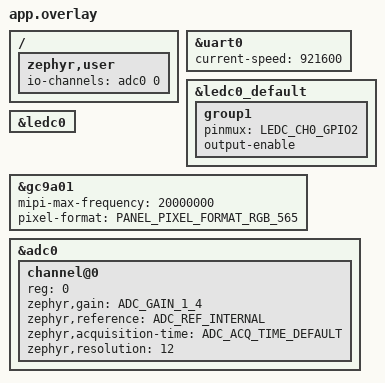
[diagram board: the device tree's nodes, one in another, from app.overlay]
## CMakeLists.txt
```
cmake_minimum_required(VERSION 3.20.0)
find_package(Zephyr REQUIRED HINTS $ENV{ZEPHYR_BASE})
project(esp32_face_os)

target_sources(app PRIVATE
    src/main.c
    src/ui_screens.c
    src/imu_qmi8658.c
    src/ble_scanner.c
    src/gpio_agent.c
    src/serial_proto.c
)
```

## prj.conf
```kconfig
CONFIG_MAIN_STACK_SIZE=8192
CONFIG_SYSTEM_WORKQUEUE_STACK_SIZE=4096
CONFIG_HEAP_MEM_POOL_SIZE=40960
CONFIG_SYS_HEAP_RUNTIME_STATS=y

# Display & Peripherals
CONFIG_DISPLAY=y
CONFIG_PWM=y
CONFIG_GPIO=y
CONFIG_I2C=y
CONFIG_ADC=y

# Touch Input
CONFIG_INPUT=y
CONFIG_INPUT_CST816S=y
CONFIG_INPUT_CST816S_INTERRUPT=y
CONFIG_LV_Z_POINTER_INPUT=y

# LVGL Configuration
CONFIG_LVGL=y
CONFIG_LV_MEM_CUSTOM=y
CONFIG_LV_Z_MEM_POOL_SIZE=49152
CONFIG_LV_COLOR_DEPTH_16=y
CONFIG_LV_USE_IMG=y
CONFIG_LV_USE_LABEL=y
CONFIG_LV_USE_BTN=y
CONFIG_LV_USE_ARC=y
CONFIG_LV_USE_BAR=y
CONFIG_LV_USE_SLIDER=y
CONFIG_LV_USE_SWITCH=y
CONFIG_LV_FONT_MONTSERRAT_12=y
CONFIG_LV_FONT_MONTSERRAT_14=y
CONFIG_LV_FONT_MONTSERRAT_18=y
CONFIG_LV_FONT_MONTSERRAT_24=y

# Bluetooth LE Observer (Passive Proximity Scanner)
CONFIG_BT=y
CONFIG_BT_OBSERVER=y
CONFIG_BT_DEVICE_NAME="CompanionFace"

# Serial / UART Protocol (921600 NDJSON, zero console/log interleaving on UART0)
CONFIG_SERIAL=y
CONFIG_UART_INTERRUPT_DRIVEN=y
CONFIG_PICOLIBC_IO_FLOAT=y
CONFIG_BOOT_BANNER=n
CONFIG_CONSOLE=n
CONFIG_UART_CONSOLE=n
CONFIG_LOG_BACKEND_UART=n
CONFIG_PRINTK=n
CONFIG_LOG=n
```

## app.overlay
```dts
#include <zephyr/dt-bindings/adc/adc.h>
#include <zephyr/dt-bindings/pinctrl/esp32s3-pinctrl.h>

/ {
	zephyr,user {
		io-channels = <&adc0 0>;
	};
};

&uart0 {
	current-speed = <921600>;
};

&ledc0_default {
	group1 {
		pinmux = <LEDC_CH0_GPIO2>;
		output-enable;
	};
};

&ledc0 {
	status = "okay";
};

&gc9a01 {
	mipi-max-frequency = <20000000>;
	pixel-format = <PANEL_PIXEL_FORMAT_RGB_565>;
};

&adc0 {
	status = "okay";
	#address-cells = <1>;
	#size-cells = <0>;

	channel@0 {
		reg = <0>;
		zephyr,gain = "ADC_GAIN_1_4";
		zephyr,reference = "ADC_REF_INTERNAL";
		zephyr,acquisition-time = <ADC_ACQ_TIME_DEFAULT>;
		zephyr,resolution = <12>;
	};
};
```

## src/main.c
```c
/*
 * Companion Face OS Front for Waveshare ESP32-S3-Touch-LCD-1.28-B
 * Built on Zephyr RTOS v3.7 + LVGL v8.4
 */

#include <stdio.h>
#include <zephyr/device.h>
#include <zephyr/devicetree.h>
#include <zephyr/drivers/display.h>
#include <zephyr/kernel.h>
#include <lvgl.h>

#include "ble_scanner.h"
#include "gpio_agent.h"
#include "imu_qmi8658.h"
#include "serial_proto.h"
#include "ui_screens.h"

static void on_face_tap_cb(bool currently_speaking)
{
    if (currently_speaking) {
        serial_send_json("{\"t\":\"evt\",\"src\":\"touch\",\"act\":\"stop_speech\"}");
        ui_set_emotion(FACE_IDLE);
    } else {
        serial_send_json("{\"t\":\"evt\",\"src\":\"touch\",\"act\":\"ptt_toggle\"}");
    }
}

static void on_cfg_change_cb(int bright, int vol, const char *mic_mode, int ble_en, int sleep_s)
{
    char buf[160];
    snprintf(buf, sizeof(buf),
             "{\"t\":\"evt\",\"src\":\"cfg\",\"bright\":%d,\"vol\":%d,\"mode\":\"%s\",\"ble_en\":%d,\"sleep_s\":%d}",
             bright, vol, mic_mode, ble_en, sleep_s);
    serial_send_json(buf);
}

static void on_dbg_test_call_cb(void)
{
    serial_send_json("{\"t\":\"evt\",\"src\":\"dbg\",\"act\":\"test_call\"}");
}

static void on_dbg_ble_refresh_cb(void)
{
    serial_send_ble_evt();
}

static void on_net_refresh_cb(void)
{
    serial_send_json("{\"t\":\"evt\",\"src\":\"net\",\"act\":\"refresh\"}");
}

int main(void)
{
    /* 1. Initialize Display & LVGL UI (PWM backlight GPIO 2 initialized in ui_screens_init) */
    const struct device *display_dev = DEVICE_DT_GET(DT_CHOSEN(zephyr_display));
    if (!device_is_ready(display_dev)) {
        return 0;
    }

    ui_callbacks_t ui_cbs = {
        .on_face_tap = on_face_tap_cb,
        .on_cfg_change = on_cfg_change_cb,
        .on_dbg_test_call = on_dbg_test_call_cb,
        .on_dbg_ble_refresh = on_dbg_ble_refresh_cb,
        .on_net_refresh = on_net_refresh_cb,
    };
    ui_screens_init(&ui_cbs);
    lv_task_handler();
    display_blanking_off(display_dev);

    /* 2. Initialize Subsystems (IMU launches dedicated 50Hz thread) */
    gpio_agent_init();
    imu_qmi8658_init();
    ble_scanner_init();
    serial_proto_init();

    serial_send_json("{\"t\":\"evt\",\"src\":\"sys\",\"act\":\"boot\",\"ver\":\"1.0\"}");

    uint32_t loop_tick = 0;

    while (1) {
        /* Drain UART NDJSON commands immediately */
        serial_proto_poll();

        /* Drain 50Hz IMU gesture events */
        imu_gesture_event_t imu_ev;
        while (imu_qmi8658_pop_gesture(&imu_ev)) {
            char ev[160];
            snprintf(ev, sizeof(ev),
                     "{\"t\":\"evt\",\"src\":\"imu\",\"gest\":\"%s\",\"ax\":%.2f,\"ay\":%.2f,\"az\":%.2f,\"temp\":%.1f}",
                     imu_gesture_to_str(imu_ev.gest),
                     (double)imu_ev.ax, (double)imu_ev.ay, (double)imu_ev.az,
                     (double)imu_ev.temp_c);
            serial_send_json(ev);
        }

        /* Animate procedural face at ~33 FPS (every 30ms) */
        if ((loop_tick % 3) == 0) {
            ui_screens_tick_anim();
        }

        /* Update Debug & Battery telemetry every 500ms */
        if ((loop_tick % 50) == 0) {
            ui_screens_update_telemetry();
        }

        /* Periodic 10-second heartbeat */
        if ((loop_tick % 1000) == 0 && loop_tick > 0) {
            char hb[96];
            snprintf(hb, sizeof(hb), "{\"t\":\"evt\",\"src\":\"sys\",\"act\":\"hb\",\"up\":%lld}",
                     k_uptime_get());
            serial_send_json(hb);
        }

        lv_task_handler();
        loop_tick++;
        k_sleep(K_MSEC(10));
    }

    return 0;
}
```

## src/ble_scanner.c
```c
#include "ble_scanner.h"

#include <stdio.h>
#include <string.h>
#include <zephyr/bluetooth/bluetooth.h>
#include <zephyr/bluetooth/hci.h>
#include <zephyr/kernel.h>
#include <zephyr/logging/log.h>

LOG_MODULE_REGISTER(ble_scanner, LOG_LEVEL_WRN);

#define BLE_STALE_MS 30000

static struct k_mutex ble_mutex;
static ble_device_entry_t dev_table[BLE_MAX_DEVICES];
static bool bt_initialized;
static bool scan_enabled;

static void sanitize_name(const uint8_t *src, size_t len, char *dst, size_t dst_size)
{
    size_t j = 0;
    for (size_t i = 0; i < len && j + 1 < dst_size; i++) {
        char c = (char)src[i];
        if (c >= 0x20 && c <= 0x7E && c != '"' && c != '\\') {
            dst[j++] = c;
        }
    }
    dst[j] = '\0';
}

static bool parse_ad_name_cb(struct bt_data *data, void *user_data)
{
    char *name_buf = (char *)user_data;
    if (data->type == BT_DATA_NAME_COMPLETE || data->type == BT_DATA_NAME_SHORTENED) {
        sanitize_name(data->data, data->data_len, name_buf, 32);
        return false; /* stop parsing */
    }
    return true;
}

static void prune_stale_locked(int64_t now)
{
    for (int i = 0; i < BLE_MAX_DEVICES; i++) {
        if (dev_table[i].active && (now - dev_table[i].last_seen_ms) > BLE_STALE_MS) {
            dev_table[i].active = false;
        }
    }
}

static void scan_cb(const bt_addr_le_t *addr, int8_t rssi, uint8_t type,
                    struct net_buf_simple *ad)
{
    ARG_UNUSED(type);

    char mac_str[18];
    snprintf(mac_str, sizeof(mac_str), "%02X:%02X:%02X:%02X:%02X:%02X",
             addr->a.val[5], addr->a.val[4], addr->a.val[3],
             addr->a.val[2], addr->a.val[1], addr->a.val[0]);

    char parsed_name[32] = {0};
    if (ad != NULL && ad->len > 0) {
        bt_data_parse(ad, parse_ad_name_cb, parsed_name);
    }

    int64_t now = k_uptime_get();

    k_mutex_lock(&ble_mutex, K_FOREVER);
    prune_stale_locked(now);

    int empty_idx = -1;
    int oldest_idx = 0;
    int64_t oldest_ts = INT64_MAX;
    int match_idx = -1;

    for (int i = 0; i < BLE_MAX_DEVICES; i++) {
        if (dev_table[i].active) {
            if (strcmp(dev_table[i].mac, mac_str) == 0 &&
                dev_table[i].addr_type == addr->type) {
                match_idx = i;
                break;
            }
            if (dev_table[i].last_seen_ms < oldest_ts) {
                oldest_ts = dev_table[i].last_seen_ms;
                oldest_idx = i;
            }
        } else if (empty_idx < 0) {
            empty_idx = i;
        }
    }

    int target = (match_idx >= 0) ? match_idx : ((empty_idx >= 0) ? empty_idx : oldest_idx);
    dev_table[target].active = true;
    dev_table[target].addr_type = addr->type;
    strncpy(dev_table[target].mac, mac_str, sizeof(dev_table[target].mac) - 1);
    dev_table[target].mac[sizeof(dev_table[target].mac) - 1] = '\0';
    dev_table[target].rssi = rssi;
    dev_table[target].last_seen_ms = now;

    if (parsed_name[0] != '\0') {
        strncpy(dev_table[target].name, parsed_name, sizeof(dev_table[target].name) - 1);
        dev_table[target].name[sizeof(dev_table[target].name) - 1] = '\0';
    } else if (match_idx < 0) {
        dev_table[target].name[0] = '\0';
    }

    k_mutex_unlock(&ble_mutex);
}

int ble_scanner_init(void)
{
    k_mutex_init(&ble_mutex);
    memset(dev_table, 0, sizeof(dev_table));

    int err = bt_enable(NULL);
    if (err) {
        LOG_ERR("bt_enable failed (%d)", err);
        return err;
    }
    bt_initialized = true;
    return ble_scanner_set_enabled(true);
}

int ble_scanner_set_enabled(bool enable)
{
    if (!bt_initialized) {
        return -ENODEV;
    }
    if (enable == scan_enabled) {
        return 0;
    }

    if (enable) {
        struct bt_le_scan_param scan_param = {
            .type = BT_LE_SCAN_TYPE_PASSIVE,
            .options = BT_LE_SCAN_OPT_NONE,
            .interval = BT_GAP_SCAN_FAST_INTERVAL,
            .window = BT_GAP_SCAN_FAST_WINDOW,
        };
        int err = bt_le_scan_start(&scan_param, scan_cb);
        if (err) {
            LOG_ERR("bt_le_scan_start failed (%d)", err);
            return err;
        }
        scan_enabled = true;
    } else {
        int err = bt_le_scan_stop();
        if (err) {
            LOG_ERR("bt_le_scan_stop failed (%d)", err);
            return err;
        }
        scan_enabled = false;
    }

    return 0;
}

bool ble_scanner_is_enabled(void)
{
    return scan_enabled;
}

int ble_scanner_get_count(void)
{
    int count = 0;
    int64_t now = k_uptime_get();

    k_mutex_lock(&ble_mutex, K_FOREVER);
    prune_stale_locked(now);
    for (int i = 0; i < BLE_MAX_DEVICES; i++) {
        if (dev_table[i].active) {
            count++;
        }
    }
    k_mutex_unlock(&ble_mutex);

    return count;
}

bool ble_scanner_get_strongest(char *mac_out, size_t mac_len,
                               char *name_out, size_t name_len,
                               int8_t *rssi_out)
{
    int64_t now = k_uptime_get();
    int best_idx = -1;
    int8_t best_rssi = INT8_MIN;

    k_mutex_lock(&ble_mutex, K_FOREVER);
    prune_stale_locked(now);
    for (int i = 0; i < BLE_MAX_DEVICES; i++) {
        if (dev_table[i].active && (best_idx < 0 || dev_table[i].rssi > best_rssi)) {
            best_rssi = dev_table[i].rssi;
            best_idx = i;
        }
    }

    if (best_idx >= 0) {
        if (mac_out && mac_len > 0) {
            strncpy(mac_out, dev_table[best_idx].mac, mac_len - 1);
            mac_out[mac_len - 1] = '\0';
        }
        if (name_out && name_len > 0) {
            strncpy(name_out, dev_table[best_idx].name, name_len - 1);
            name_out[name_len - 1] = '\0';
        }
        if (rssi_out) {
            *rssi_out = best_rssi;
        }
    }
    k_mutex_unlock(&ble_mutex);

    return best_idx >= 0;
}

int ble_scanner_format_json_ex(char *buf, size_t len, int *cnt_out)
{
    if (!buf || len < 3) {
        return -EINVAL;
    }

    int64_t now = k_uptime_get();
    size_t pos = 0;
    buf[pos++] = '[';
    bool first = true;
    int count = 0;

    k_mutex_lock(&ble_mutex, K_FOREVER);
    prune_stale_locked(now);

    for (int i = 0; i < BLE_MAX_DEVICES; i++) {
        if (!dev_table[i].active) {
            continue;
        }
        char entry[128];
        int n = snprintf(entry, sizeof(entry),
                         "%s{\"mac\":\"%s\",\"type\":%u,\"name\":\"%s\",\"rssi\":%d}",
                         first ? "" : ",",
                         dev_table[i].mac,
                         (unsigned int)dev_table[i].addr_type,
                         dev_table[i].name[0] ? dev_table[i].name : "?",
                         (int)dev_table[i].rssi);
        if (n < 0 || (size_t)n >= sizeof(entry) || pos + (size_t)n + 2 > len) {
            break;
        }
        memcpy(buf + pos, entry, (size_t)n);
        pos += (size_t)n;
        first = false;
        count++;
    }
    k_mutex_unlock(&ble_mutex);

    if (cnt_out) {
        *cnt_out = count;
    }
    buf[pos++] = ']';
    buf[pos] = '\0';
    return (int)pos;
}

int ble_scanner_format_json(char *buf, size_t len)
{
    return ble_scanner_format_json_ex(buf, len, NULL);
}
```

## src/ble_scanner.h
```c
#ifndef BLE_SCANNER_H
#define BLE_SCANNER_H

#include <stdbool.h>
#include <stddef.h>
#include <stdint.h>

#define BLE_MAX_DEVICES 32

typedef struct {
    bool active;
    uint8_t addr_type;
    char mac[18];
    char name[32];
    int8_t rssi;
    int64_t last_seen_ms;
} ble_device_entry_t;

/**
 * @brief Initialize Zephyr BLE stack and start passive observer scanning.
 * @return 0 on success, negative errno on failure.
 */
int ble_scanner_init(void);

/**
 * @brief Enable or pause background BLE passive scanning.
 */
int ble_scanner_set_enabled(bool enable);

/**
 * @brief Check whether BLE scanning is currently active.
 */
bool ble_scanner_is_enabled(void);

/**
 * @brief Return count of active devices seen within the last 30 seconds.
 */
int ble_scanner_get_count(void);

/**
 * @brief Retrieve strongest currently visible device (if any).
 * @return true if at least one active device exists.
 */
bool ble_scanner_get_strongest(char *mac_out, size_t mac_len,
                               char *name_out, size_t name_len,
                               int8_t *rssi_out);

/**
 * @brief Format active BLE devices as a JSON array into buf: [{"mac":"...","type":0,"name":"...","rssi":-50},...]
 */
int ble_scanner_format_json(char *buf, size_t len);

/**
 * @brief Format active BLE devices as a JSON array and output exact serialized count under one lock.
 */
int ble_scanner_format_json_ex(char *buf, size_t len, int *cnt_out);

#endif /* BLE_SCANNER_H */
```

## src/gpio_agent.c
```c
#include "gpio_agent.h"

#include <errno.h>
#include <stdio.h>
#include <string.h>
#include <zephyr/device.h>
#include <zephyr/devicetree.h>
#include <zephyr/drivers/adc.h>
#include <zephyr/drivers/gpio.h>
#include <zephyr/kernel.h>
#include <zephyr/logging/log.h>

LOG_MODULE_REGISTER(gpio_agent, LOG_LEVEL_WRN);

static const int allowed_pins[] = { 15, 16, 17, 18, 21, 33, 34, 35, 36, 37 };
#define NUM_ALLOWED_PINS (sizeof(allowed_pins) / sizeof(allowed_pins[0]))

static const struct device *gpio0_dev;
static const struct device *gpio1_dev;
static bool pin_configured_out[NUM_ALLOWED_PINS];
static bool pin_configured_in[NUM_ALLOWED_PINS];
static char last_gpio_status[40] = "GPIO: idle";
static struct k_mutex gpio_mutex;

#if DT_NODE_EXISTS(DT_PATH(zephyr_user)) && DT_NODE_HAS_PROP(DT_PATH(zephyr_user), io_channels)
static const struct adc_dt_spec vbat_adc = ADC_DT_SPEC_GET_BY_IDX(DT_PATH(zephyr_user), 0);
static bool adc_ready;
#else
static bool adc_ready;
#endif

static int resolve_pin(int pin, const struct device **port_out, gpio_pin_t *pin_out, int *slot_out)
{
    for (int i = 0; i < (int)NUM_ALLOWED_PINS; i++) {
        if (allowed_pins[i] == pin) {
            if (pin < 32) {
                if (!gpio0_dev || !device_is_ready(gpio0_dev)) {
                    return -ENODEV;
                }
                *port_out = gpio0_dev;
                *pin_out = (gpio_pin_t)pin;
            } else {
                if (!gpio1_dev || !device_is_ready(gpio1_dev)) {
                    return -ENODEV;
                }
                *port_out = gpio1_dev;
                *pin_out = (gpio_pin_t)(pin - 32);
            }
            if (slot_out) {
                *slot_out = i;
            }
            return 0;
        }
    }
    return -EACCES;
}

int gpio_agent_init(void)
{
    k_mutex_init(&gpio_mutex);
    memset(pin_configured_out, 0, sizeof(pin_configured_out));
    memset(pin_configured_in, 0, sizeof(pin_configured_in));

    gpio0_dev = DEVICE_DT_GET(DT_NODELABEL(gpio0));
    gpio1_dev = DEVICE_DT_GET(DT_NODELABEL(gpio1));

#if DT_NODE_EXISTS(DT_PATH(zephyr_user)) && DT_NODE_HAS_PROP(DT_PATH(zephyr_user), io_channels)
    if (adc_is_ready_dt(&vbat_adc)) {
        int err = adc_channel_setup_dt(&vbat_adc);
        if (err == 0) {
            adc_ready = true;
        } else {
            LOG_WRN("adc_channel_setup_dt failed: %d", err);
        }
    }
#endif

    return 0;
}

static int configure_pin_locked(int pin, const struct device *port, gpio_pin_t hw_pin,
                                int slot, const char *dir, const char *pull, int initial_val)
{
    gpio_flags_t flags = 0;
    bool is_out = (dir != NULL && strcmp(dir, "out") == 0);

    if (is_out) {
        flags = GPIO_INPUT | (initial_val ? GPIO_OUTPUT_HIGH : GPIO_OUTPUT_LOW);
    } else {
        flags = GPIO_INPUT;
        if (pull != NULL) {
            if (strcmp(pull, "up") == 0) {
                flags |= GPIO_PULL_UP;
            } else if (strcmp(pull, "down") == 0) {
                flags |= GPIO_PULL_DOWN;
            }
        }
    }

    int err = gpio_pin_configure(port, hw_pin, flags);
    if (err == 0) {
        pin_configured_out[slot] = is_out;
        pin_configured_in[slot] = !is_out;
        snprintf(last_gpio_status, sizeof(last_gpio_status), "P%d %s=%d",
                 pin, is_out ? "OUT" : "IN", is_out ? (initial_val ? 1 : 0) : 0);
    } else {
        snprintf(last_gpio_status, sizeof(last_gpio_status), "P%d ERR %d", pin, err);
    }
    return err;
}

static bool is_valid_dir(const char *dir)
{
    return dir != NULL && (strcmp(dir, "in") == 0 || strcmp(dir, "out") == 0);
}

static bool is_valid_pull(const char *pull)
{
    return pull == NULL || strcmp(pull, "none") == 0 ||
           strcmp(pull, "up") == 0 || strcmp(pull, "down") == 0;
}

int gpio_agent_configure(int pin, const char *dir, const char *pull, int initial_val)
{
    if (!is_valid_dir(dir) || !is_valid_pull(pull)) {
        return -EINVAL;
    }

    const struct device *port = NULL;
    gpio_pin_t hw_pin = 0;
    int slot = -1;

    int err = resolve_pin(pin, &port, &hw_pin, &slot);
    if (err != 0) {
        k_mutex_lock(&gpio_mutex, K_FOREVER);
        snprintf(last_gpio_status, sizeof(last_gpio_status), "GPIO %d: DENIED", pin);
        k_mutex_unlock(&gpio_mutex);
        return err;
    }

    k_mutex_lock(&gpio_mutex, K_FOREVER);
    err = configure_pin_locked(pin, port, hw_pin, slot, dir, pull, initial_val);
    k_mutex_unlock(&gpio_mutex);

    return err;
}

int gpio_agent_set(int pin, int val)
{
    const struct device *port = NULL;
    gpio_pin_t hw_pin = 0;
    int slot = -1;

    int err = resolve_pin(pin, &port, &hw_pin, &slot);
    if (err != 0) {
        return err;
    }

    k_mutex_lock(&gpio_mutex, K_FOREVER);
    if (!pin_configured_out[slot]) {
        err = configure_pin_locked(pin, port, hw_pin, slot, "out", "none", val ? 1 : 0);
        k_mutex_unlock(&gpio_mutex);
        return err;
    }

    err = gpio_pin_set(port, hw_pin, val ? 1 : 0);
    if (err == 0) {
        snprintf(last_gpio_status, sizeof(last_gpio_status), "P%d OUT=%d", pin, val ? 1 : 0);
    }
    k_mutex_unlock(&gpio_mutex);

    return err;
}

int gpio_agent_get(int pin, int *val_out)
{
    const struct device *port = NULL;
    gpio_pin_t hw_pin = 0;
    int slot = -1;

    int err = resolve_pin(pin, &port, &hw_pin, &slot);
    if (err != 0) {
        return err;
    }

    k_mutex_lock(&gpio_mutex, K_FOREVER);
    if (!pin_configured_out[slot] && !pin_configured_in[slot]) {
        err = configure_pin_locked(pin, port, hw_pin, slot, "in", "none", 0);
        if (err != 0) {
            k_mutex_unlock(&gpio_mutex);
            return err;
        }
    }

    int val = gpio_pin_get(port, hw_pin);
    if (val < 0) {
        k_mutex_unlock(&gpio_mutex);
        return val;
    }

    if (val_out) {
        *val_out = val;
    }

    snprintf(last_gpio_status, sizeof(last_gpio_status), "P%d READ=%d", pin, val);
    k_mutex_unlock(&gpio_mutex);

    return 0;
}

int gpio_agent_read_vbat_mv(void)
{
#if DT_NODE_EXISTS(DT_PATH(zephyr_user)) && DT_NODE_HAS_PROP(DT_PATH(zephyr_user), io_channels)
    k_mutex_lock(&gpio_mutex, K_FOREVER);
    if (!adc_ready) {
        k_mutex_unlock(&gpio_mutex);
        return 0;
    }

    int16_t buf = 0;
    struct adc_sequence seq = {
        .buffer = &buf,
        .buffer_size = sizeof(buf),
    };

    if (adc_sequence_init_dt(&vbat_adc, &seq) < 0) {
        k_mutex_unlock(&gpio_mutex);
        return 0;
    }
    if (adc_read_dt(&vbat_adc, &seq) < 0) {
        k_mutex_unlock(&gpio_mutex);
        return 0;
    }
    k_mutex_unlock(&gpio_mutex);

    int32_t mv = buf;
    if (adc_raw_to_millivolts_dt(&vbat_adc, &mv) < 0) {
        /* Fallback for 12-bit ADC with ~3.1V full scale at 11dB/1_4 gain */
        mv = ((int32_t)buf * 3100) / 4095;
    }

    /* Waveshare 200k + 100k resistor divider scales Vbat by 1/3 */
    return (int)(mv * 3);
#else
    return 0;
#endif
}

void gpio_agent_get_status_str(char *buf, size_t len)
{
    if (!buf || len == 0) return;
    k_mutex_lock(&gpio_mutex, K_FOREVER);
    strncpy(buf, last_gpio_status, len - 1);
    buf[len - 1] = '\0';
    k_mutex_unlock(&gpio_mutex);
}
```

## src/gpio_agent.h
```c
#ifndef GPIO_AGENT_H
#define GPIO_AGENT_H

#include <stdbool.h>
#include <stddef.h>

/**
 * @brief Initialize GPIO agent and battery ADC channel.
 */
int gpio_agent_init(void);

/**
 * @brief Configure an allowlisted header GPIO pin dynamically.
 * @param pin GPIO number (allowlist: 15,16,17,18,21,33,34,35,36,37)
 * @param dir "in" or "out"
 * @param pull "none", "up", or "down"
 * @param initial_val 0 or 1 (for output)
 * @return 0 on success, -EACCES if reserved, negative errno otherwise.
 */
int gpio_agent_configure(int pin, const char *dir, const char *pull, int initial_val);

/**
 * @brief Set an allowlisted GPIO output level (auto-configures as output if needed).
 */
int gpio_agent_set(int pin, int val);

/**
 * @brief Read an allowlisted GPIO pin state (returns 0 or 1 in val_out).
 */
int gpio_agent_get(int pin, int *val_out);

/**
 * @brief Read battery voltage in millivolts (scaled for 1/3 voltage divider on GPIO 1).
 */
int gpio_agent_read_vbat_mv(void);

/**
 * @brief Get human-readable summary of last agent GPIO operation for the debug screen.
 */
void gpio_agent_get_status_str(char *buf, size_t len);

#endif /* GPIO_AGENT_H */
```

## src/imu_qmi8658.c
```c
#include "imu_qmi8658.h"

#include <math.h>
#include <string.h>
#include <zephyr/device.h>
#include <zephyr/drivers/i2c.h>
#include <zephyr/kernel.h>
#include <zephyr/logging/log.h>
#include <zephyr/sys/byteorder.h>

LOG_MODULE_REGISTER(imu_qmi8658, LOG_LEVEL_WRN);

#define QMI8658_ADDR_PRIMARY   0x6B
#define QMI8658_ADDR_ALT       0x6A

#define QMI8658_REG_WHO_AM_I   0x00
#define QMI8658_REG_CTRL1      0x02
#define QMI8658_REG_CTRL2      0x03
#define QMI8658_REG_CTRL3      0x04
#define QMI8658_REG_CTRL7      0x08
#define QMI8658_REG_TEMP_L     0x33

#define QMI8658_WHO_AM_I_VAL   0x05

#define GESTURE_COOLDOWN_MS    800
#define IMU_THREAD_STACK_SIZE  2048
#define IMU_THREAD_PRIO        K_PRIO_PREEMPT(2)

typedef enum {
    TAP_IDLE = 0,
    TAP_FIRST_ACTIVE,
    TAP_WAIT_SECOND,
    TAP_SECOND_ACTIVE,
} tap_state_t;

static const struct device *i2c_dev;
static struct k_mutex imu_mutex;
static imu_data_t g_imu;
static int shake_score;
static bool was_tilted;
static bool lp_init;
static float lp_ax, lp_ay, lp_az;
static int lp_freeze_ticks;
static bool prev_init;
static float prev_ax, prev_ay, prev_az;
static int rest_flat_ticks;
static bool was_resting_flat;
static int pickup_ticks;
static int pickup_drop_ticks;
static bool pickup_ref_set;
static bool pickup_active;
static bool pickup_dipped;
static float pickup_ref_ax, pickup_ref_ay;
static float pickup_dir_ax, pickup_dir_ay;
static tap_state_t tap_state;
static int64_t tap1_ms;
static int64_t tap2_ms;
static int tap_quiet_ticks;
static int tap2_steady_ticks;
static float tap1_base_ax, tap1_base_ay, tap1_base_az;
static float tap2_base_ax, tap2_base_ay, tap2_base_az;
static int64_t last_shake_ms;

K_MSGQ_DEFINE(imu_evt_msgq, sizeof(imu_gesture_event_t), 8, 4);
K_THREAD_STACK_DEFINE(imu_thread_stack, IMU_THREAD_STACK_SIZE);
static struct k_thread imu_thread_data;
static void imu_thread_fn(void *p1, void *p2, void *p3);

static int qmi_write_reg(uint8_t addr, uint8_t reg, uint8_t val)
{
    uint8_t buf[2] = { reg, val };
    return i2c_write(i2c_dev, buf, sizeof(buf), addr);
}

static int qmi_read_regs(uint8_t addr, uint8_t reg, uint8_t *dst, size_t len)
{
    return i2c_write_read(i2c_dev, addr, &reg, 1, dst, len);
}

static int try_probe_addr(uint8_t addr)
{
    uint8_t who = 0;
    int ret = qmi_read_regs(addr, QMI8658_REG_WHO_AM_I, &who, 1);
    if (ret < 0) {
        return ret;
    }
    if (who != QMI8658_WHO_AM_I_VAL) {
        return -ENODEV;
    }
    return 0;
}

int imu_qmi8658_init(void)
{
    k_mutex_init(&imu_mutex);
    memset(&g_imu, 0, sizeof(g_imu));
    shake_score = 0;
    was_tilted = false;
    lp_init = false;
    lp_ax = lp_ay = lp_az = 0.0f;
    lp_freeze_ticks = 0;
    prev_init = false;
    prev_ax = prev_ay = prev_az = 0.0f;
    rest_flat_ticks = 0;
    was_resting_flat = false;
    pickup_ticks = 0;
    pickup_drop_ticks = 0;
    pickup_ref_set = false;
    pickup_active = false;
    pickup_dipped = false;
    pickup_ref_ax = pickup_ref_ay = 0.0f;
    pickup_dir_ax = pickup_dir_ay = 0.0f;
    tap_state = TAP_IDLE;
    tap1_ms = 0;
    tap2_ms = 0;
    tap_quiet_ticks = 0;
    tap2_steady_ticks = 0;
    tap1_base_ax = tap1_base_ay = tap1_base_az = 0.0f;
    tap2_base_ax = tap2_base_ay = tap2_base_az = 0.0f;
    last_shake_ms = -1000;

    i2c_dev = DEVICE_DT_GET(DT_NODELABEL(i2c1));
    if (!device_is_ready(i2c_dev)) {
        LOG_ERR("i2c1 not ready");
        return -ENODEV;
    }

    uint8_t addr = QMI8658_ADDR_PRIMARY;
    if (try_probe_addr(addr) != 0) {
        addr = QMI8658_ADDR_ALT;
        if (try_probe_addr(addr) != 0) {
            LOG_ERR("QMI8658 not found at 0x6B or 0x6A");
            return -ENODEV;
        }
    }

    /* CTRL1: auto-increment address, little endian */
    if (qmi_write_reg(addr, QMI8658_REG_CTRL1, 0x40) < 0) return -EIO;
    /* CTRL2: Accel +/-8g (0x2_), 250Hz (0x_5) */
    if (qmi_write_reg(addr, QMI8658_REG_CTRL2, 0x25) < 0) return -EIO;
    /* CTRL3: Gyro +/-512dps (0x5_), 250Hz (0x_5) */
    if (qmi_write_reg(addr, QMI8658_REG_CTRL3, 0x55) < 0) return -EIO;
    /* CTRL7: Enable Accel + Gyro */
    if (qmi_write_reg(addr, QMI8658_REG_CTRL7, 0x03) < 0) return -EIO;

    k_mutex_lock(&imu_mutex, K_FOREVER);
    g_imu.ready = true;
    g_imu.addr = addr;
    g_imu.last_gesture = IMU_GESTURE_NONE;
    k_mutex_unlock(&imu_mutex);

    k_thread_create(&imu_thread_data, imu_thread_stack,
                    K_THREAD_STACK_SIZEOF(imu_thread_stack),
                    imu_thread_fn, NULL, NULL, NULL,
                    IMU_THREAD_PRIO, 0, K_NO_WAIT);
    k_thread_name_set(&imu_thread_data, "imu_50hz");

    return 0;
}

static imu_gesture_t imu_qmi8658_poll(imu_data_t *out)
{
    imu_gesture_t triggered = IMU_GESTURE_NONE;
    bool ready = false;
    uint8_t addr = 0;

    k_mutex_lock(&imu_mutex, K_FOREVER);
    ready = g_imu.ready;
    addr = g_imu.addr;
    k_mutex_unlock(&imu_mutex);

    if (!ready || i2c_dev == NULL) {
        if (out) {
            imu_qmi8658_get_latest(out);
        }
        return IMU_GESTURE_NONE;
    }

    uint8_t raw[14];
    if (qmi_read_regs(addr, QMI8658_REG_TEMP_L, raw, sizeof(raw)) < 0) {
        if (out) {
            imu_qmi8658_get_latest(out);
        }
        return IMU_GESTURE_NONE;
    }

    int16_t raw_temp = (int16_t)sys_get_le16(&raw[0]);
    int16_t raw_ax   = (int16_t)sys_get_le16(&raw[2]);
    int16_t raw_ay   = (int16_t)sys_get_le16(&raw[4]);
    int16_t raw_az   = (int16_t)sys_get_le16(&raw[6]);
    int16_t raw_gx   = (int16_t)sys_get_le16(&raw[8]);
    int16_t raw_gy   = (int16_t)sys_get_le16(&raw[10]);
    int16_t raw_gz   = (int16_t)sys_get_le16(&raw[12]);

    float ax = ((float)raw_ax) * (9.80665f / 4096.0f);
    float ay = ((float)raw_ay) * (9.80665f / 4096.0f);
    float az = ((float)raw_az) * (9.80665f / 4096.0f);
    float gx = ((float)raw_gx) / 64.0f;
    float gy = ((float)raw_gy) / 64.0f;
    float gz = ((float)raw_gz) / 64.0f;
    float temp_c = ((float)raw_temp) / 256.0f;

    int64_t now = k_uptime_get();

    if (!prev_init) {
        prev_ax = ax;
        prev_ay = ay;
        prev_az = az;
        prev_init = true;
    }
    float jx = ax - prev_ax;
    float jy = ay - prev_ay;
    float jz = az - prev_az;
    float jerk = sqrtf(jx * jx + jy * jy + jz * jz);
    prev_ax = ax;
    prev_ay = ay;
    prev_az = az;

    float a_mag = sqrtf(ax * ax + ay * ay + az * az);

    if (!lp_init) {
        lp_ax = ax;
        lp_ay = ay;
        lp_az = az;
        lp_init = true;
        lp_freeze_ticks = 0;
    }

    float dx = ax - lp_ax;
    float dy = ay - lp_ay;
    float dz = az - lp_az;
    float dyn_mag = sqrtf(dx * dx + dy * dy + dz * dz);

    /* Freeze low-pass gravity adaptation on sharp tap impulses (up to 15 ticks = 300ms),
     * while allowing steady 1g orientation changes to track gravity smoothly. */
    bool steady_1g = (jerk < 3.0f) && (fabsf(a_mag - 9.80665f) < 1.5f);
    if (dyn_mag <= 2.2f || steady_1g || lp_freeze_ticks >= 15) {
        lp_ax += 0.15f * (ax - lp_ax);
        lp_ay += 0.15f * (ay - lp_ay);
        lp_az += 0.15f * (az - lp_az);
        dx = ax - lp_ax;
        dy = ay - lp_ay;
        dz = az - lp_az;
        dyn_mag = sqrtf(dx * dx + dy * dy + dz * dz);
        lp_freeze_ticks = 0;
    } else {
        lp_freeze_ticks++;
    }

    float in_plane = sqrtf(ax * ax + ay * ay);
    float gyro_mag = fabsf(gx) + fabsf(gy) + fabsf(gz);
    bool is_tilted = (fabsf(ax) > 6.5f) || (fabsf(ay) > 6.5f);

    if (dyn_mag > 7.0f && !steady_1g) {
        shake_score += 2;
        if (shake_score > 16) {
            shake_score = 16;
        }
    } else if (shake_score > 0) {
        shake_score--;
    }

    if (was_resting_flat) {
        if (in_plane > 5.5f) {
            pickup_active = true;
            pickup_drop_ticks = 0;
            if (!pickup_ref_set || pickup_dipped) {
                pickup_ref_ax = ax;
                pickup_ref_ay = ay;
                pickup_ref_set = true;
                pickup_dipped = false;
            } else if ((shake_score >= 10) ||
                       (shake_score >= 4 && dyn_mag > 7.0f && a_mag > 12.0f &&
                        (ax * pickup_ref_ax + ay * pickup_ref_ay) < -15.0f)) {
                /* High-energy shake or lateral reversal: not a pickup/twist */
                was_resting_flat = false;
                rest_flat_ticks = 0;
                pickup_ticks = 0;
                pickup_drop_ticks = 0;
                pickup_ref_set = false;
                pickup_active = false;
                pickup_dipped = false;
            }
        } else {
            bool clear_flat = false;
            if (shake_score >= 4) {
                clear_flat = true;
            } else if (pickup_active) {
                if (in_plane < 3.5f) {
                    clear_flat = true;
                } else if (in_plane <= 4.5f) {
                    pickup_drop_ticks++;
                    pickup_dipped = true;
                    if (pickup_drop_ticks >= 2) {
                        clear_flat = true;
                    }
                } else {
                    pickup_drop_ticks = 0;
                }
            }
            if (clear_flat) {
                was_resting_flat = false;
                rest_flat_ticks = 0;
                pickup_ticks = 0;
                pickup_drop_ticks = 0;
                pickup_ref_set = false;
                pickup_active = false;
                pickup_dipped = false;
            }
        }
    }

    if (shake_score >= 10 || (now - last_shake_ms) <= 500) {
        tap_state = TAP_IDLE;
    }

    if (in_plane < 3.0f && dyn_mag < 1.5f && gyro_mag < 30.0f) {
        if (rest_flat_ticks < 25) {
            rest_flat_ticks++;
        }
        if (rest_flat_ticks >= 15) {
            was_resting_flat = true;
            pickup_ref_set = false;
            pickup_drop_ticks = 0;
            pickup_active = false;
            pickup_dipped = false;
        }
    } else {
        rest_flat_ticks = 0;
    }

    bool dbl_tap_fired = false;
    switch (tap_state) {
    case TAP_IDLE:
        if (dyn_mag > 4.0f && gyro_mag < 220.0f &&
            (now - last_shake_ms) > 500 && shake_score < 8) {
            tap1_ms = now;
            tap1_base_ax = lp_ax;
            tap1_base_ay = lp_ay;
            tap1_base_az = lp_az;
            tap_quiet_ticks = 0;
            tap_state = TAP_FIRST_ACTIVE;
        }
        break;
    case TAP_FIRST_ACTIVE:
        if ((now - tap1_ms) > 140) {
            tap_state = TAP_IDLE;
        } else if (dyn_mag < 2.2f) {
            float bx = ax - tap1_base_ax;
            float by = ay - tap1_base_ay;
            float bz = az - tap1_base_az;
            float bdiff = sqrtf(bx * bx + by * by + bz * bz);
            if (bdiff > 3.5f) {
                tap_state = TAP_IDLE;
            } else {
                tap_quiet_ticks = 1;
                tap2_base_ax = lp_ax;
                tap2_base_ay = lp_ay;
                tap2_base_az = lp_az;
                tap_state = TAP_WAIT_SECOND;
            }
        }
        break;
    case TAP_WAIT_SECOND: {
        int64_t dt = now - tap1_ms;
        if (dt > 450) {
            tap_state = TAP_IDLE;
        } else if (dyn_mag < 2.2f) {
            tap_quiet_ticks++;
            tap2_base_ax = lp_ax;
            tap2_base_ay = lp_ay;
            tap2_base_az = lp_az;
        } else if (dt < 120) {
            if (dyn_mag > 4.0f) {
                tap_state = TAP_IDLE;
            } else {
                tap_quiet_ticks = 0;
            }
        } else if (dyn_mag > 4.0f && gyro_mag < 220.0f) {
            if (tap_quiet_ticks >= 2) {
                tap2_ms = now;
                tap2_steady_ticks = 0;
                tap_quiet_ticks = 0;
                tap_state = TAP_SECOND_ACTIVE;
            } else {
                tap_state = TAP_IDLE;
            }
        }
        break;
    }
    case TAP_SECOND_ACTIVE: {
        int64_t dt2 = now - tap2_ms;
        float bx = ax - tap2_base_ax;
        float by = ay - tap2_base_ay;
        float bz = az - tap2_base_az;
        float bdiff = sqrtf(bx * bx + by * by + bz * bz);
        if (dt2 > 120) {
            tap_state = TAP_IDLE;
        } else if (steady_1g && bdiff > 3.5f) {
            tap2_steady_ticks++;
            if (tap2_steady_ticks >= 4) {
                tap_state = TAP_IDLE;
            }
        } else if (dyn_mag < 2.2f) {
            if (bdiff > 3.5f) {
                tap_state = TAP_IDLE;
            } else {
                tap_quiet_ticks++;
                if (tap_quiet_ticks >= 3 && shake_score < 10) {
                    dbl_tap_fired = true;
                    tap_state = TAP_IDLE;
                }
            }
        } else {
            if (tap_quiet_ticks > 0 && dyn_mag > 3.5f) {
                tap_state = TAP_IDLE;
            } else {
                tap_quiet_ticks = 0;
            }
        }
        break;
    }
    }

    bool settled = steady_1g || (dyn_mag <= 7.0f);
    bool flat_lateral = (fabsf(az) > 8.5f);
    if (was_resting_flat && in_plane > 5.5f && settled && shake_score < 4 && !flat_lateral) {
        if (pickup_ticks == 0) {
            pickup_dir_ax = ax;
            pickup_dir_ay = ay;
            pickup_ticks = 1;
        } else {
            float dot = ax * pickup_dir_ax + ay * pickup_dir_ay;
            float dir_m2 = pickup_dir_ax * pickup_dir_ax + pickup_dir_ay * pickup_dir_ay;
            float cur_m2 = ax * ax + ay * ay;
            if (dot <= 0.0f || (dot * dot) < 0.88f * dir_m2 * cur_m2) {
                pickup_dir_ax = ax;
                pickup_dir_ay = ay;
                pickup_ticks = 1;
            } else {
                pickup_ticks++;
            }
        }
    } else {
        pickup_ticks = 0;
    }

    k_mutex_lock(&imu_mutex, K_FOREVER);
    g_imu.ax = ax;
    g_imu.ay = ay;
    g_imu.az = az;
    g_imu.gx = gx;
    g_imu.gy = gy;
    g_imu.gz = gz;
    g_imu.temp_c = temp_c;

    if ((now - g_imu.last_gesture_ms) >= GESTURE_COOLDOWN_MS) {
        if (shake_score >= 10 && (!was_resting_flat || in_plane <= 5.5f)) {
            triggered = IMU_GESTURE_SHAKE;
            g_imu.last_gesture = IMU_GESTURE_SHAKE;
            g_imu.last_gesture_ms = now;
            shake_score = 0;
            last_shake_ms = now;
            tap_state = TAP_IDLE;
            was_resting_flat = false;
            rest_flat_ticks = 0;
            pickup_ticks = 0;
            pickup_drop_ticks = 0;
            pickup_ref_set = false;
            pickup_active = false;
            pickup_dipped = false;
        } else if (shake_score < 4 && was_resting_flat && pickup_ticks >= 3) {
            triggered = IMU_GESTURE_PICKUP;
            g_imu.last_gesture = IMU_GESTURE_PICKUP;
            g_imu.last_gesture_ms = now;
            was_resting_flat = false;
            rest_flat_ticks = 0;
            pickup_ticks = 0;
            pickup_drop_ticks = 0;
            pickup_ref_set = false;
            pickup_active = false;
            pickup_dipped = false;
        } else if (dbl_tap_fired) {
            triggered = IMU_GESTURE_DOUBLE_TAP;
            g_imu.last_gesture = IMU_GESTURE_DOUBLE_TAP;
            g_imu.last_gesture_ms = now;
        } else if (shake_score < 4 && is_tilted && !was_tilted &&
                   settled && !was_resting_flat && !flat_lateral) {
            triggered = IMU_GESTURE_TILT;
            g_imu.last_gesture = IMU_GESTURE_TILT;
            g_imu.last_gesture_ms = now;
        }
    }

    if (pickup_ticks >= 3) {
        was_resting_flat = false;
        rest_flat_ticks = 0;
        pickup_ticks = 0;
        pickup_drop_ticks = 0;
        pickup_ref_set = false;
        pickup_active = false;
        pickup_dipped = false;
    }
    was_tilted = is_tilted;

    if (out) {
        *out = g_imu;
    }
    k_mutex_unlock(&imu_mutex);

    return triggered;
}

static void imu_thread_fn(void *p1, void *p2, void *p3)
{
    ARG_UNUSED(p1);
    ARG_UNUSED(p2);
    ARG_UNUSED(p3);

    int64_t next_ms = k_uptime_get();
    while (1) {
        imu_data_t snap;
        imu_gesture_t gest = imu_qmi8658_poll(&snap);
        if (gest != IMU_GESTURE_NONE) {
            imu_gesture_event_t ev = {
                .gest = gest,
                .ax = snap.ax,
                .ay = snap.ay,
                .az = snap.az,
                .temp_c = snap.temp_c,
            };
            k_msgq_put(&imu_evt_msgq, &ev, K_NO_WAIT);
        }

        next_ms += 20;
        int64_t rem = next_ms - k_uptime_get();
        if (rem > 0) {
            k_msleep((int32_t)rem);
        } else if (rem < -100) {
            next_ms = k_uptime_get();
        }
    }
}

bool imu_qmi8658_pop_gesture(imu_gesture_event_t *out)
{
    if (!out) return false;
    return k_msgq_get(&imu_evt_msgq, out, K_NO_WAIT) == 0;
}

void imu_qmi8658_get_latest(imu_data_t *out)
{
    if (!out) return;
    k_mutex_lock(&imu_mutex, K_FOREVER);
    *out = g_imu;
    k_mutex_unlock(&imu_mutex);
}

const char *imu_gesture_to_str(imu_gesture_t g)
{
    switch (g) {
    case IMU_GESTURE_SHAKE:
        return "shake";
    case IMU_GESTURE_TILT:
        return "tilt";
    case IMU_GESTURE_PICKUP:
        return "pickup";
    case IMU_GESTURE_DOUBLE_TAP:
        return "double_tap";
    default:
        return "none";
    }
}
```

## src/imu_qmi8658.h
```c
#ifndef IMU_QMI8658_H
#define IMU_QMI8658_H

#include <stdbool.h>
#include <stdint.h>

typedef enum {
    IMU_GESTURE_NONE = 0,
    IMU_GESTURE_SHAKE,
    IMU_GESTURE_TILT,
    IMU_GESTURE_PICKUP,
    IMU_GESTURE_DOUBLE_TAP,
} imu_gesture_t;

typedef struct {
    imu_gesture_t gest;
    float ax;
    float ay;
    float az;
    float temp_c;
} imu_gesture_event_t;

typedef struct {
    bool ready;
    uint8_t addr;
    float ax;
    float ay;
    float az;
    float gx;
    float gy;
    float gz;
    float temp_c;
    imu_gesture_t last_gesture;
    int64_t last_gesture_ms;
} imu_data_t;

/**
 * @brief Initialize the QMI8658 6-axis IMU over i2c1.
 * @return 0 on success, negative errno on failure.
 */
int imu_qmi8658_init(void);

/**
 * @brief Pop the next queued gesture event detected by the 50Hz IMU thread.
 * @return true if an event was popped into out, false if queue is empty.
 */
bool imu_qmi8658_pop_gesture(imu_gesture_event_t *out);

/**
 * @brief Get cached latest IMU state.
 */
void imu_qmi8658_get_latest(imu_data_t *out);

/**
 * @brief Convert gesture enum to static string.
 */
const char *imu_gesture_to_str(imu_gesture_t g);

#endif /* IMU_QMI8658_H */
```

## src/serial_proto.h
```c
#ifndef SERIAL_PROTO_H
#define SERIAL_PROTO_H

/**
 * @brief Initialize interrupt-driven UART0 NDJSON serial handler.
 */
int serial_proto_init(void);

/**
 * @brief Send a newline-terminated JSON string safely over UART0.
 */
void serial_send_json(const char *json_line);

/**
 * @brief Drain queued NDJSON commands and dispatch to UI / GPIO / BLE / IMU.
 */
void serial_proto_poll(void);

/**
 * @brief Format and transmit an asynchronous BLE device list event.
 */
void serial_send_ble_evt(void);

#endif /* SERIAL_PROTO_H */
```

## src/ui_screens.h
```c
#ifndef UI_SCREENS_H
#define UI_SCREENS_H

#include <stdbool.h>
#include <stdint.h>

typedef enum {
    FACE_IDLE = 0,
    FACE_LISTENING,
    FACE_THINKING,
    FACE_SPEAKING,
    FACE_HAPPY,
    FACE_SAD,
    FACE_SURPRISED,
    FACE_SLEEPING,
    FACE_ALERT,
} face_emotion_t;

typedef struct {
    void (*on_face_tap)(bool currently_speaking);
    void (*on_cfg_change)(int bright, int vol, const char *mic_mode, int ble_en, int sleep_s);
    void (*on_dbg_test_call)(void);
    void (*on_dbg_ble_refresh)(void);
    void (*on_net_refresh)(void);
} ui_callbacks_t;

/**
 * @brief Initialize all 3 LVGL screens (Face, Settings, Debug) and load Home screen.
 */
void ui_screens_init(const ui_callbacks_t *cbs);

/**
 * @brief Periodic ~33FPS UI animation & 360-degree gravity rotation tick.
 */
void ui_screens_tick_anim(void);

/**
 * @brief Refresh telemetry labels on the Debug screen and Home battery/status.
 */
void ui_screens_update_telemetry(void);

/**
 * @brief Get current smoothed UI rotation angle in degrees (0..359).
 */
int ui_screens_get_angle_deg(void);

/**
 * @brief Set companion emotional expression by enum or string.
 */
void ui_set_emotion(face_emotion_t emo);
void ui_set_emotion_str(const char *emo_str);

/**
 * @brief Update bottom live subtitle box on the Face screen.
 */
void ui_set_subtitle(const char *text);

/**
 * @brief Update real-time mouth openness (0..100) for lip-sync viseme animation.
 */
void ui_set_mouth(int value);

/**
 * @brief Update QuIXI / VoIP / BT link status shown on Home & Debug screens.
 */
void ui_set_link_status(const char *quixi, const char *voip, int rtt_ms, const char *bt_spk);

/**
 * @brief Update Raspberry Pi DHCP IP address and QuIXI Ixian wallet address on the Network screen.
 */
void ui_set_network_info(const char *rpi_ip, const char *ixian_addr);

/**
 * @brief Update current mic active state (listening indicator).
 */
void ui_set_mic_active(bool active);

/**
 * @brief Host-callable non-echoing config setters (update PWM / UI without emitting evt.cfg).
 */
void ui_set_brightness(int pct);
int ui_get_brightness(void);
void ui_set_volume(int vol);
void ui_set_mic_mode_str(const char *mode);
void ui_set_ble_enabled_ui(bool enabled);
void ui_set_sleep_timeout_s(int sleep_s);

/**
 * @brief Full-screen RGB565 image/video frame overlay (120x120 scaled 2x to 240x240).
 */
#define UI_MEDIA_W 120
#define UI_MEDIA_H 120
#define UI_MEDIA_BYTES (UI_MEDIA_W * UI_MEDIA_H * 2)

uint8_t *ui_media_get_buffer(void);
void ui_media_present(int w, int h);
void ui_media_clear(void);

#endif /* UI_SCREENS_H */
```
